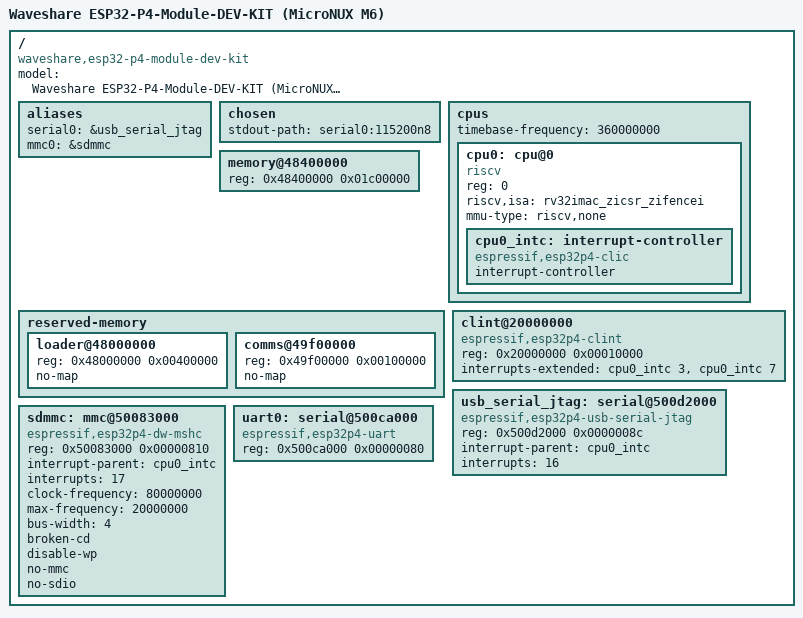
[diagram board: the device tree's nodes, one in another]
// SPDX-License-Identifier: GPL-2.0-only
/dts-v1/;

/ {
	model = "Waveshare ESP32-P4-Module-DEV-KIT (MicroNUX M6)";
	compatible = "waveshare,esp32-p4-module-dev-kit", "espressif,esp32p4";
	#address-cells = <1>;
	#size-cells = <1>;

	aliases {
		serial0 = &usb_serial_jtag;
		mmc0 = &sdmmc;
	};

	chosen {
		stdout-path = "serial0:115200n8";
	};

	cpus {
		#address-cells = <1>;
		#size-cells = <0>;
		timebase-frequency = <360000000>;

		cpu0: cpu@0 {
			compatible = "riscv";
			device_type = "cpu";
			reg = <0>;
			status = "okay";
			riscv,isa = "rv32imac_zicsr_zifencei";
			mmu-type = "riscv,none";

			cpu0_intc: interrupt-controller {
				compatible = "espressif,esp32p4-clic";
				interrupt-controller;
				#interrupt-cells = <1>;
			};
		};
	};

	memory@48400000 {
		device_type = "memory";
		reg = <0x48400000 0x01c00000>;
	};

	reserved-memory {
		#address-cells = <1>;
		#size-cells = <1>;
		ranges;

		loader@48000000 {
			reg = <0x48000000 0x00400000>;
			no-map;
		};

		comms@49f00000 {
			reg = <0x49f00000 0x00100000>;
			no-map;
		};
	};

	clint@20000000 {
		compatible = "espressif,esp32p4-clint";
		reg = <0x20000000 0x00010000>;
		interrupts-extended = <&cpu0_intc 3>, <&cpu0_intc 7>;
	};

	usb_serial_jtag: serial@500d2000 {
		compatible = "espressif,esp32p4-usb-serial-jtag";
		reg = <0x500d2000 0x0000008c>;
		interrupt-parent = <&cpu0_intc>;
		interrupts = <16>;
		status = "okay";
	};

	sdmmc: mmc@50083000 {
		compatible = "espressif,esp32p4-dw-mshc";
		reg = <0x50083000 0x00000810>;
		interrupt-parent = <&cpu0_intc>;
		interrupts = <17>;
		clock-frequency = <80000000>;
		max-frequency = <20000000>;
		bus-width = <4>;
		broken-cd;
		disable-wp;
		no-mmc;
		no-sdio;
		status = "okay";
	};

	uart0: serial@500ca000 {
		compatible = "espressif,esp32p4-uart";
		reg = <0x500ca000 0x00000080>;
		status = "okay";
	};
};
